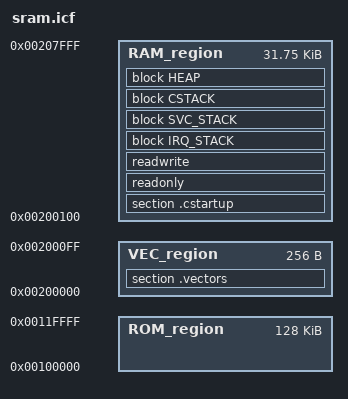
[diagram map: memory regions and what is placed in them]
/*###ICF### Section handled by ICF editor, don't touch! ****/
/*-Editor annotation file-*/
/* IcfEditorFile="$TOOLKIT_DIR$\config\ide\IcfEditor\a_v1_0.xml" */
/*-Memory Regions-*/
define symbol __ICFEDIT_region_ROM_start__   = 0x100000;
define symbol __ICFEDIT_region_ROM_end__     = 0x11FFFF;
define symbol __ICFEDIT_region_RAM_start__   = 0x200000;
define symbol __ICFEDIT_region_RAM_end__     = 0x207FFF;
/*-Sizes-*/
define symbol __ICFEDIT_size_vectors__  = 0x100;
define symbol __ICFEDIT_size_cstack__   = 0x1000;
define symbol __ICFEDIT_size_svcstack__ = 0x60;
define symbol __ICFEDIT_size_irqstack__ = 0x60;
/**** End of ICF editor section. ###ICF###*/

define memory mem with size = 4G;
define region ROM_region = mem:[from __ICFEDIT_region_ROM_start__ to __ICFEDIT_region_ROM_end__];
define region VEC_region = mem:[from __ICFEDIT_region_RAM_start__ size __ICFEDIT_size_vectors__];
define region RAM_region = mem:[from __ICFEDIT_region_RAM_start__+__ICFEDIT_size_vectors__ to __ICFEDIT_region_RAM_end__];

define block CSTACK    with alignment = 4, size = __ICFEDIT_size_cstack__   { };
define block SVC_STACK with alignment = 4, size = __ICFEDIT_size_svcstack__ { };
define block IRQ_STACK with alignment = 4, size = __ICFEDIT_size_irqstack__ { };
define block HEAP      with alignment = 4, size = 0 { };

do not initialize  { section .noinit };

place in VEC_region { section .vectors };
place in RAM_region { section .cstartup, readonly, readwrite, block IRQ_STACK, block SVC_STACK, block CSTACK, block HEAP };
